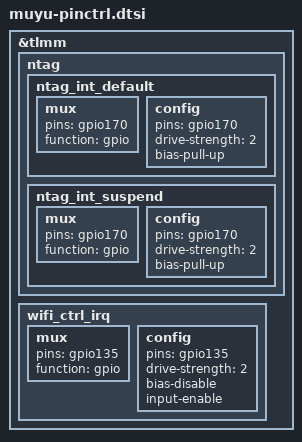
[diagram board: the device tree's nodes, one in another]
/*for muyu pinctrl */
&tlmm {
	ntag {
		ntag_int_default: ntag_int_default {
			mux {
				pins = "gpio170";
				function = "gpio";
			};

			config {
				pins = "gpio170";
				drive-strength = <2>; /* 2 MA */
				bias-pull-up;
			};
		};

		ntag_int_suspend: ntag_int_suspend {
			mux {
				pins = "gpio170";
				function = "gpio";
			};

			config {
				pins = "gpio170";
				drive-strength = <2>; /* 2 MA */
				bias-pull-up;
			};
		};
	}; //ntag

        wifi_ctrl_irq: wifi_ctrl_irq {
                mux {
                        pins = "gpio135";
                        function = "gpio";
                };

                config {
                        pins = "gpio135";
                        drive-strength = <2>;   /* 2 mA */
                        bias-disable;
                        input-enable;
                };
        }; //wifi
}; //tlmm
